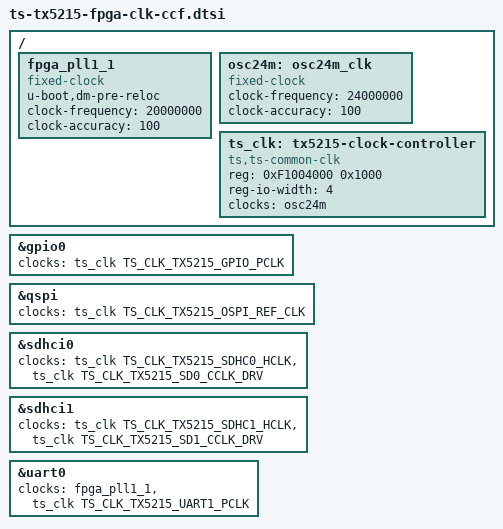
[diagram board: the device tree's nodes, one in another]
// SPDX-License-Identifier: GPL-2.0+
/*
 * dts file for tsingmicro tx5215
 *
 * Copyright 2022 Beijing Tsingmicro Intelligent Technology Co.,Ltd.
 *
 */

#include <dt-bindings/clock/ts-tx5215-clk.h>
/ {

	fpga_pll1_1: fpga_pll1_1 {
		u-boot,dm-pre-reloc;
		compatible = "fixed-clock";
		#clock-cells = <0>;
		clock-frequency = <20000000>;
		clock-accuracy = <100>;
	};

	osc24m: osc24m_clk {
		compatible = "fixed-clock";
		#clock-cells = <0>;
		clock-frequency = <24000000>;
		clock-accuracy = <100>;	
	};

	ts_clk: tx5215-clock-controller {
		reg = <0xF1004000 0x1000>;
		reg-io-width = <4>;
		#clock-cells = <1>;
		compatible = "ts,ts-common-clk";
		clocks = <&osc24m>;					
		/* clkcfg_num = <2>; */
		/* clkcfg_arr = <TS_CLK_BT1120TX_HCLK 0 3675000>, <TS_CLK_GDC_MCLK 0 249000000>; */	
	};

};

&gpio0 {
	clocks = <&ts_clk TS_CLK_TX5215_GPIO_PCLK>;
};

&qspi {
	clocks = <&ts_clk TS_CLK_TX5215_OSPI_REF_CLK>;
	clock-names = "ospi_refclk";
};

&sdhci0 {
	clocks = <&ts_clk TS_CLK_TX5215_SDHC0_HCLK>, <&ts_clk TS_CLK_TX5215_SD0_CCLK_DRV>;
	clock-names = "biu", "ciu";
};

&sdhci1 {
	clocks = <&ts_clk TS_CLK_TX5215_SDHC1_HCLK>, <&ts_clk TS_CLK_TX5215_SD1_CCLK_DRV>;
	clock-names = "biu", "ciu";
};

&uart0 {
	clocks = <&fpga_pll1_1>, <&ts_clk TS_CLK_TX5215_UART1_PCLK>;
};

